# CH32H417 register map
Vendor: WCH Ltd.; File version: 1.2
Registers are 32-bit, read-write, reset 0x0 unless marked. A register's access mark holds for its fields unless they carry their own. Offsets are from the block's base; [hi:lo] are bit positions; {n}, {i} and the like mark numbered series.

## AFIO — Alternate function I/O
Base 0x40010000
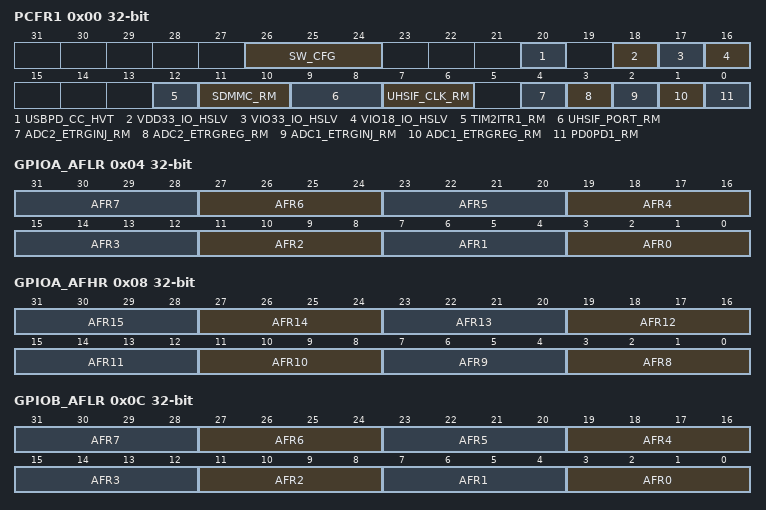
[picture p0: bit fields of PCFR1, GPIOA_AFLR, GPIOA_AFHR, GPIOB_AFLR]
0x00 PCFR1 — AF remap and debug I/O configuration register (AFIO_PCFR1)
  [26:24] SW_CFG — Serial wire JTAG configuration
  [20] USBPD_CC_HVT — CC pin intput channel threshold adjustment
  [18] VDD33_IO_HSLV — VDD33 IO speed configuration at low voltage
  [17] VIO33_IO_HSLV — VIO33 IO speed configuration at low voltage
  [16] VIO18_IO_HSLV — VIO18 IO speed configuration at low voltage
  [12] TIM2ITR1_RM — TIM2ITR1 remapping
  [11:10] SDMMC_RM — SDMMC remapping
  [9:8] UHSIF_PORT_RM — UHSIF_PORT remapping
  [7:6] UHSIF_CLK_RM — UHSIF_CLK remapping
  [4] ADC2_ETRGINJ_RM — ADC2_ETRGINJ remapping
  [3] ADC2_ETRGREG_RM — ADC2_ETRGREG remapping
  [2] ADC1_ETRGINJ_RM — ADC1_ETRGINJ remapping
  [1] ADC1_ETRGREG_RM — ADC1_ETRGREG remapping
  [0] PD0PD1_RM — PD0PD1 remapping
0x04 GPIOA_AFLR — PA port multiplexing function register
  [4n+3:4n] AFR{n} (n=0..7) — selection of multiplexing function for pin {n} of PA port
0x08 GPIOA_AFHR — PA port multiplexing function register
  [4n-29:4n-32] AFR{n} (n=8..15) — selection of multiplexing function for pin {n} of PA port
0x0C GPIOB_AFLR — PB port multiplexing function register
  [4n+3:4n] AFR{n} (n=0..7) — selection of multiplexing function for pin {n} of PB port
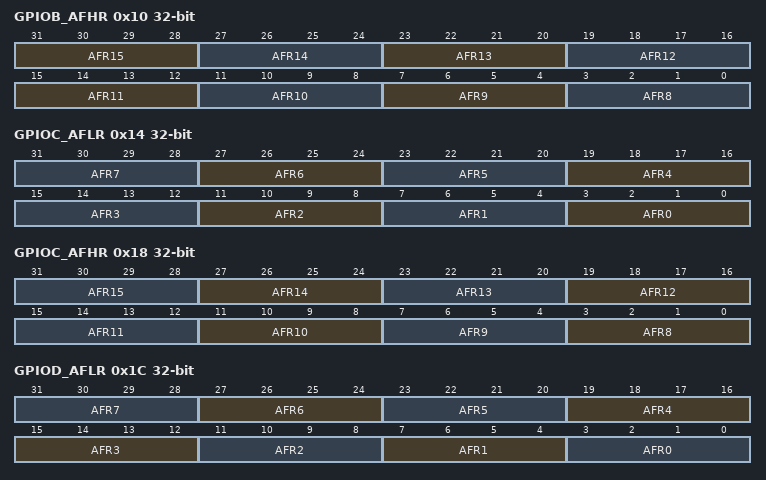
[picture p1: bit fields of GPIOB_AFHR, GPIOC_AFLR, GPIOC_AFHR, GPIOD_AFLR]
0x10 GPIOB_AFHR — PB port multiplexing function register
  [4n-29:4n-32] AFR{n} (n=9..15) — selection of multiplexing function for pin {n} of PB port
  [3:0] AFR8 — selection of multiplexing function for pin 8 of PA port
0x14 GPIOC_AFLR — PC port multiplexing function register
  [4n+3:4n] AFR{n} (n=0..7) — selection of multiplexing function for pin {n} of PC port
0x18 GPIOC_AFHR — PC port multiplexing function register
  [4n-29:4n-32] AFR{n} (n=8..15) — selection of multiplexing function for pin {n} of PC port
0x1C GPIOD_AFLR — PD port multiplexing function register
  [4n+3:4n] AFR{n} (n=4..7) — selection of multiplexing function for pin {n} of PD port
  [15:12] AFR3 — selection of multiplexing function for pin 3 of PA port
  [11:8] AFR2 — selection of multiplexing function for pin 2 of PD port
  [7:4] AFR1 — selection of multiplexing function for pin 1 of PD port
  [3:0] AFR0 — selection of multiplexing function for pin 0 of PD port
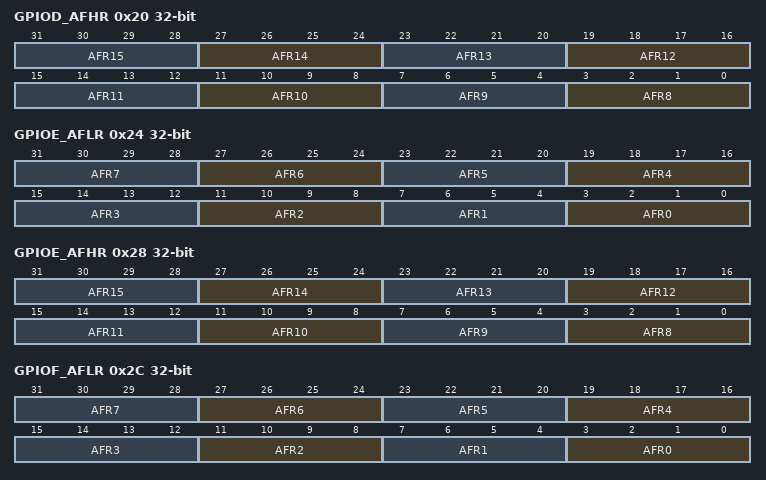
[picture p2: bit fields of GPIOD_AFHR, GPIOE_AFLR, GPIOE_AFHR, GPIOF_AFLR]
0x20 GPIOD_AFHR — PD port multiplexing function register
  [4n-29:4n-32] AFR{n} (n=8..15) — selection of multiplexing function for pin {n} of PD port
0x24 GPIOE_AFLR — PE port multiplexing function register
  [4n+3:4n] AFR{n} (n=0..7) — selection of multiplexing function for pin {n} of PE port
0x28 GPIOE_AFHR — PA port multiplexing function register
  [4n-29:4n-32] AFR{n} (n=8..15) — selection of multiplexing function for pin {n} of PE port
0x2C GPIOF_AFLR — PF port multiplexing function register
  [4n+3:4n] AFR{n} (n=0..7) — selection of multiplexing function for pin {n} of PF port
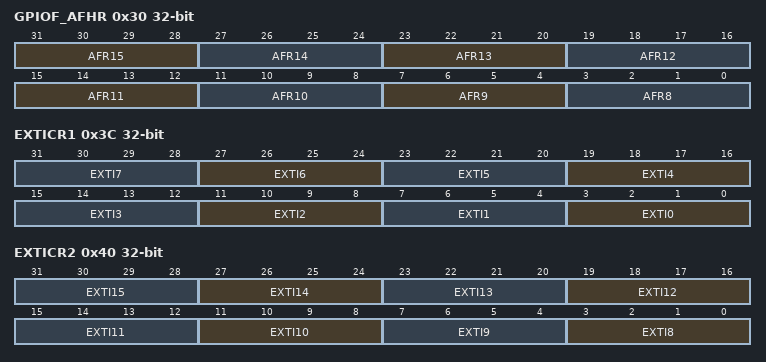
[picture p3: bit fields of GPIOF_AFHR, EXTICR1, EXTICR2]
0x30 GPIOF_AFHR — PF port multiplexing function register
  [31:28] AFR15 — selection of multiplexing function for pin 15 of PE port
  [4n-29:4n-32] AFR{n} (n=8..14) — selection of multiplexing function for pin {n} of PF port
0x3C EXTICR1 — External interrupt configuration register 1
  [4n+3:4n] EXTI{n} (n=0..7) — External interrupt {n} input pin configuration
0x40 EXTICR2 — External interrupt configuration register 2
  [4n-29:4n-32] EXTI{n} (n=8..15) — External interrupt {n} input pin configuration

## DMAMUX — DMA request multiplexer
Base 0x40020800
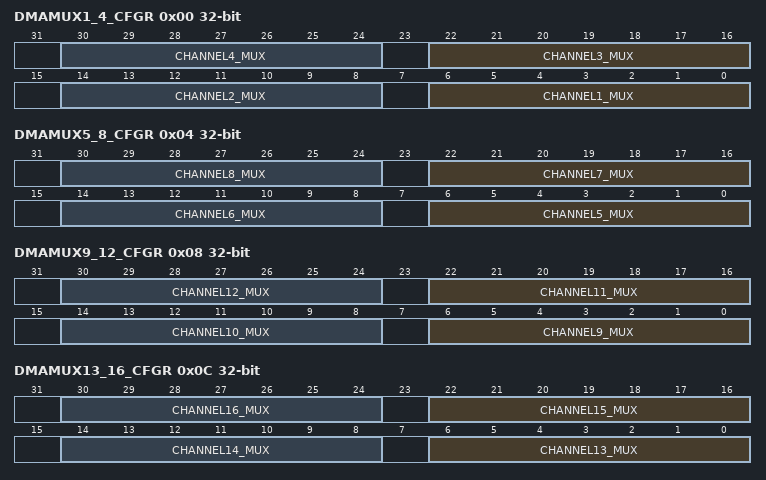
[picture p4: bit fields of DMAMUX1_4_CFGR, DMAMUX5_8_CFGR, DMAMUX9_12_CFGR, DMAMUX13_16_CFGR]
0x00 DMAMUX1_4_CFGR — DMA request multiplexer channels 1 to 4 configuration registers
  [8n-2:8n-8] CHANNEL{n}_MUX (n=1..4) — DMA request multiplexer channels {n} intput to the volunteer configuration
0x04 DMAMUX5_8_CFGR — DMA request multiplexer channels 5 to 8 configuration registers
  [8n-34:8n-40] CHANNEL{n}_MUX (n=5..8) — DMA request multiplexer channels {n} intput to the volunteer configuration
0x08 DMAMUX9_12_CFGR — DMA request multiplexer channels 9 to 12 configuration registers
  [8n-66:8n-72] CHANNEL{n}_MUX (n=9..12) — DMA request multiplexer channels {n} intput to the volunteer configuration
0x0C DMAMUX13_16_CFGR — DMA request multiplexer channels 13 to 16 configuration registers
  [8n-98:8n-104] CHANNEL{n}_MUX (n=13..16) — DMA request multiplexer channels {n} intput to the volunteer configuration
